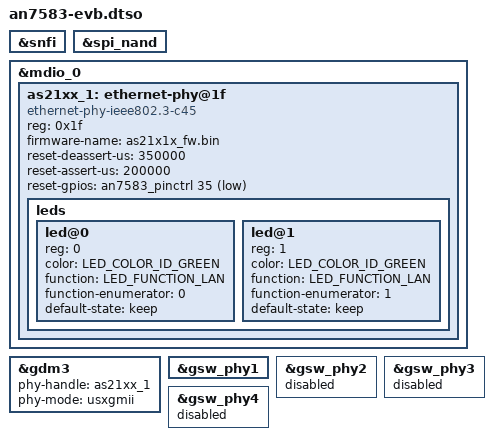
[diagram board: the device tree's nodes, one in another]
// SPDX-License-Identifier: (GPL-2.0-only OR BSD-2-Clause)
/dts-v1/;
/plugin/;

#include <dt-bindings/leds/common.h>
#include <dt-bindings/gpio/gpio.h>

&snfi {
	status = "okay";
};

&spi_nand {
	status = "okay";
};

&mdio_0 {
	/* Present but not HW connected to GDM port */
	/*
	 * as21xx_0: ethernet-phy@1d {
	 *		reg = <0x1d>;
	 *		compatible = "ethernet-phy-ieee802.3-c45";
	 *		status = "disabled";
	 *
	 *		firmware-name = "as21x1x_fw.bin";
	 *
	 *		reset-deassert-us = <350000>;
	 *		reset-assert-us = <200000>;
	 *		reset-gpios = <&an7583_pinctrl 34 GPIO_ACTIVE_LOW>;
	 *
	 *		leds {
	 *			#address-cells = <1>;
	 *			#size-cells = <0>;
	 *
	 *			led@0 {
	 *				reg = <0>;
	 *				color = <LED_COLOR_ID_GREEN>;
	 *				function = LED_FUNCTION_LAN;
	 *				function-enumerator = <0>;
	 *				default-state = "keep";
	 *			};
	 *
	 *			led@1 {
	 *				reg = <1>;
	 *				color = <LED_COLOR_ID_GREEN>;
	 *				function = LED_FUNCTION_LAN;
	 *				function-enumerator = <1>;
	 *				default-state = "keep";
	 *			};
	 *		};
	 * };
	 */

	as21xx_1: ethernet-phy@1f {
		reg = <0x1f>;
		compatible = "ethernet-phy-ieee802.3-c45";

		firmware-name = "as21x1x_fw.bin";

		reset-deassert-us = <350000>;
		reset-assert-us = <200000>;
		reset-gpios = <&an7583_pinctrl 35 GPIO_ACTIVE_LOW>;

		leds {
			#address-cells = <1>;
			#size-cells = <0>;

			led@0 {
				reg = <0>;
				color = <LED_COLOR_ID_GREEN>;
				function = LED_FUNCTION_LAN;
				function-enumerator = <0>;
				default-state = "keep";
			};

			led@1 {
				reg = <1>;
				color = <LED_COLOR_ID_GREEN>;
				function = LED_FUNCTION_LAN;
				function-enumerator = <1>;
				default-state = "keep";
			};
		};
	};
};

/* GDM2 seems to be connected to PON */
/*
 *&gdm2 {
 *	status = "disabled";
 *
 *	phy-handle = <&as21xx_0>;
 *	phy-mode = "usxgmii";
 *};
 */

&gdm3 {
	status = "okay";

	phy-handle = <&as21xx_1>;
	phy-mode = "usxgmii";
};

&gsw_phy1 {
	status = "okay";
};

&gsw_phy2 {
	status = "disabled";
};

&gsw_phy3 {
	status = "disabled";
};

&gsw_phy4 {
	status = "disabled";
};
